# FM33L0XX register map
File version: 1.0
ARM 32-bit Cortex SC000 Microcontroller based device
CPU: SC000 r1p0, little endian, no MPU, no FPU, 3 interrupt priority bits
Registers are 32-bit, read-write, reset 0x0 unless marked. A register's access mark holds for its fields unless they carry their own. Offsets are from the block's base; lines under a group give offsets from that group; [hi:lo] are bit positions; {n}, {i} and the like mark numbered series; 'fields as' and 'values as' point back to an identical list; <NAME> marks a mode.

## Memory map
0x40000000 DBG size 0x100 — Debug config unit
0x40000100 PMU size 0x100 — POWER MANAGEMENT UNIT
0x40000200 RCC size 0x200 — RESET AND CLOCK CONTROL UNIT
0x40000400 DMA size 0x200 — Peripheral DMA, Direct Memory Access
0x40000C00 GPIOA size 0x40 — GPIO PORTA
0x40000C40 GPIOB size 0x40
0x40000C80 GPIOC size 0x40
0x40000CC0 GPIOD size 0x40
0x40000D00 GPIO_COMMON size 0x300 — GPIO_COMMON Registers
0x40001000 FLS size 0x40 — NVMIF Registers
0x40010000 CRC size 0x40
0x40010400 LPUART0 size 0x20 — LPUART0 Registers
0x40010420 LPUART1 size 0x20
0x40010840 SPI1 size 0x40 — SPI Serial Peripheral Interface
0x40010880 SPI2 size 0x40
0x40010C00 LCD size 0x100 — LCD Registers
0x40011000 RTC size 0x100 — RTC Registers
0x40011400 IWDT size 0x40
0x40011800 WWDT size 0x40 — WWDT Registers
0x40011C00 U7816 size 0x2C — U7816 Registers
0x40012008 UART_COMMON size 0x4 — UART_COMMON Registers
0x4001200C UART0 size 0x20 — UART0 Registers
0x4001202C UART1 size 0x20
0x4001208C UART4 size 0x20
0x400120AC UART5 size 0x20
0x40012400 I2C size 0x50 — I2C Registers
0x40012800 RCC_PDR size 0x4 — RCC_PDR Registers
0x40012804 RCC_BOR size 0x4 — RCC_BOR Registers
0x4001280C PMU_VREF size 0xC — POWER VERF MANAGEMENT UNIT
0x40012818 PMU_BUF size 0x4 — POWER VERF MANAGEMENT UNIT
0x40012824 SVD size 0x14 — SVD Registers
0x40012838 RCC_FDET size 0x8 — RCC_FDET Registers
0x40012844 OPA1 size 0x10 — OPA1 Registers
0x40012854 OPA2 size 0x10 — OPA Registers
0x40012864 RNG_CR size 0x4 — RNG_CR Registers
0x40013400 LPTIM size 0x100 — LPTIM Registers
0x40013800 AES size 0x80 — AES Registers
0x40013C04 RNG size 0x20 — TRNG Registers
0x40014000 ATIM size 0x100 — ADVANCE TIMER Registers
0x40014400 GPTIM0 size 0x100 — GENERAL TIMER0 Registers
0x40014800 GPTIM1 size 0x100
0x40014C00 BSTIM size 0x100 — BASE TIMER Registers
0x40015000 ADC size 0x100 — ADC Registers
0x40015400 BEEPER size 0x100 — BEEPER Registers

## Interrupts
0 WWDT
1 SVD
2 RTC
3 FLS
5 ADC
7 SPI1
8 SPI2
9 LCD
10 UART0
11 UART1
12 UART4
13 UART5
15 U7816
16 LPUART1
17 I2C
19 AES
20 LPTIM
21 DMA
22 TRNG (RNG)
24 BSTIM
26 GTIMER0 (GPTIM0)
27 GPTIM1
28 ATIM
30 GPIO (GPIO_COMMON)
31 LPUART0

## DBG — Debug config unit
Base 0x40000000
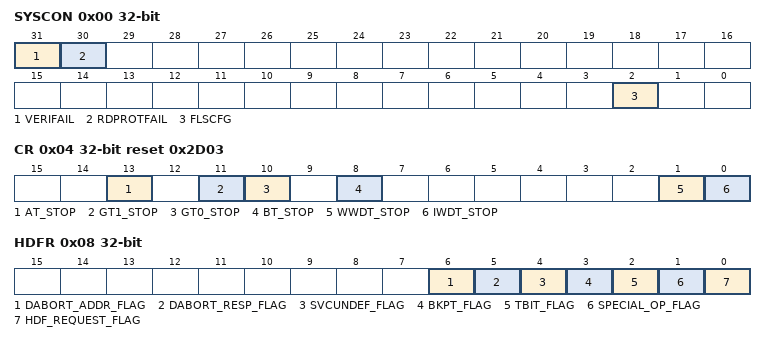
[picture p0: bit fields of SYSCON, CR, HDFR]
0x00 SYSCON ro — System Config Register
  [31] VERIFAIL — VERIFY FAIL
    0=PASS (NVR1 verify pass); 1=FAIL (NVR1 verify pass)
  [30] RDPROTFAIL — NVR5 Validation fail
    0=PASS (NVR0 Validation pass); 1=FAIL (NVR0 Validation fail)
  [2] FLSCFG — Flash Config
    0=128KB (Flash size is 128K); 1=64KB (Flash size is 64K)
0x04 CR reset 0x2D03 — debug congfig, only use at bebug mode
  [13] AT_STOP — set AT stop at debug
    0=RUNNING (AT is running); 1=STOPPED (AT is not running)
  [11] GT1_STOP — set GT2 stop at debug
    0=RUNNING (GT1 is running); 1=STOPPED (GT1 is not running)
  [10] GT0_STOP — set GT0 stop at debug
    0=RUNNING (GT0 is running); 1=STOPPED (GT0 is not running)
  [8] BT_STOP — set BT stop at debug
    0=RUNNING (BT is running); 1=STOPPED (BT is not running)
  [1] WWDT_STOP — SET WWDT STOP AT DEBUG
    0=RUNNING (wwdt is running); 1=STOPPED (wwdt is not running)
  [0] IWDT_STOP — SET IWDT STOP AT DEBUG
    0=RUNNING (iwdt is running); 1=STOPPED (iwdt is not running)
0x08 HDFR — Hard Fault Flag
  [6] DABORT_ADDR_FLAG — access adress is not alignment,write 1 to clear
    0=legal_access (no operation is address unalignment); 1=ilegal_access (some operation is address unalignment)
  [5] DABORT_RESP_FLAG — ilegal access to some address, write 1 to clear
    0=legal_access (all access is legal address); 1=ilegal_access (some access is ilegal address)
  [4] SVCUNDEF_FLAG — special operation is implimented
  [3] BKPT_FLAG — BKPT operation is implimented, Write 1 to clear
    0=NOBKPT (no BKPT operation is implimented); 1=BKPTONCE (at least one BKPT operation is implimented)
  [2] TBIT_FLAG — Thumb-State flag, write 1 to clear
    0=Thumb-State (at Thumb-State); 1=ARM_State (At ARM state)
  [1] SPECIAL_OP_FLAG — special operation is implimented
    0=NOREQ (no special operation fault is rquested); 1=REQ (Special operation fault is rquested)
  [0] HDF_REQUEST_FLAG — any hard fault is request
    0=NOREQ (no hard fault is rquested); 1=REQ (some hard fault is requested)
